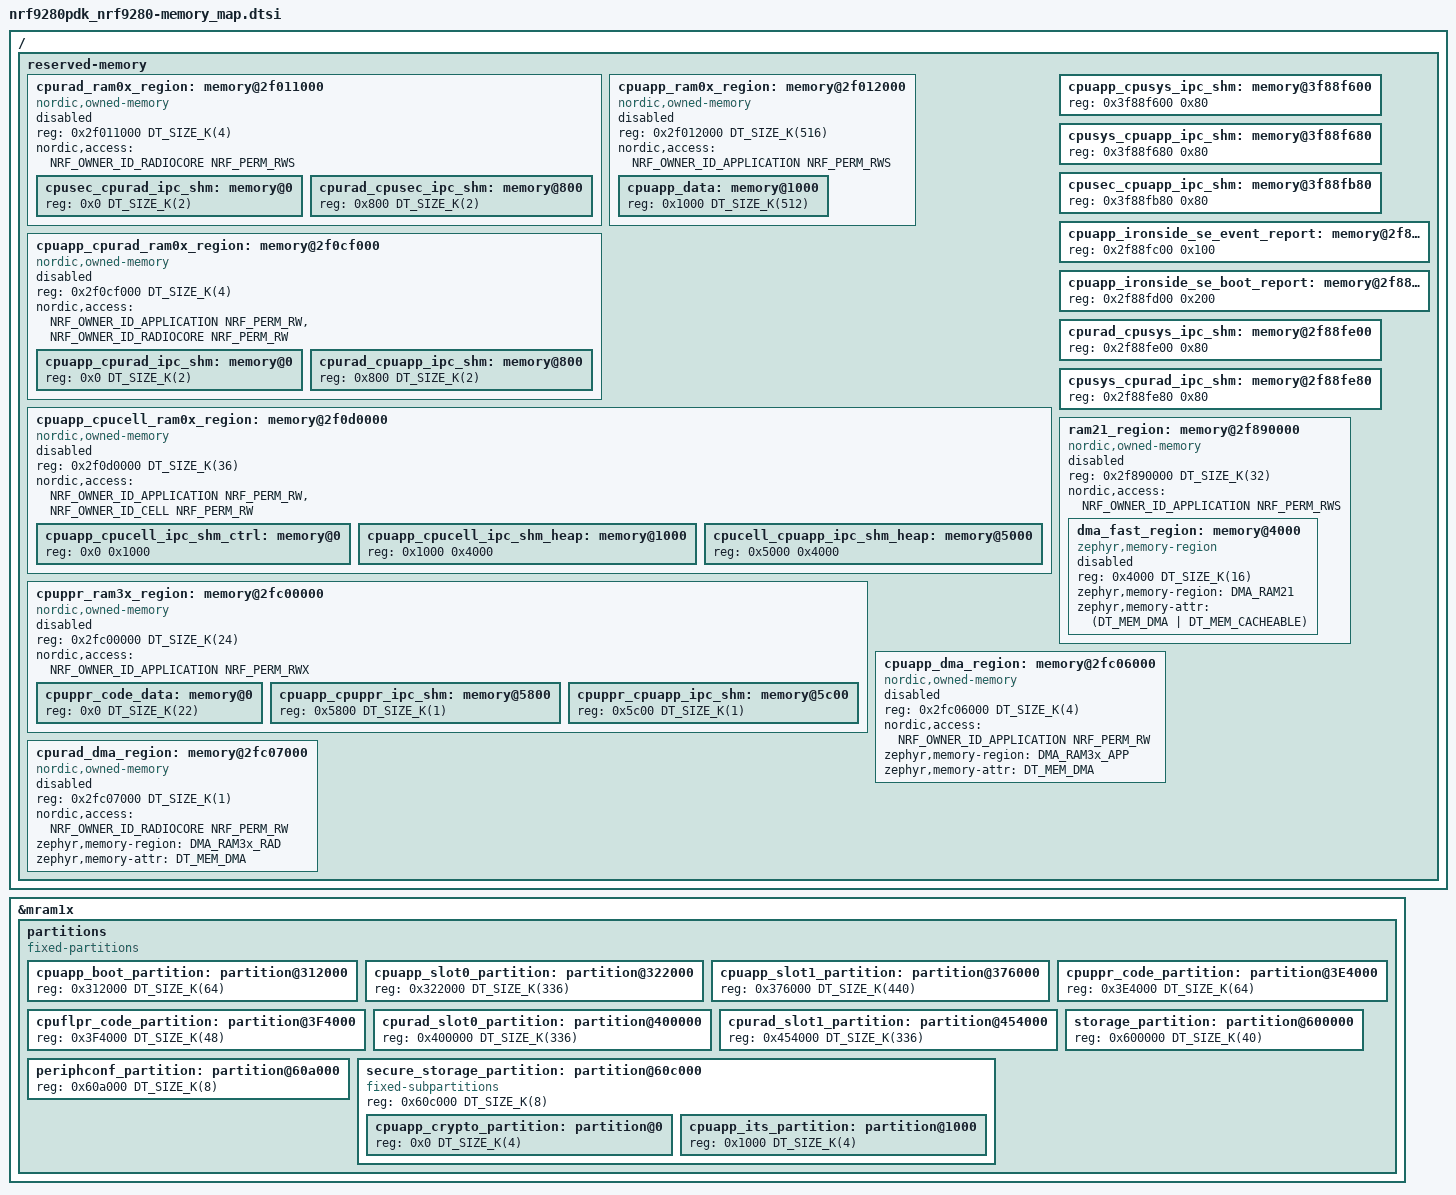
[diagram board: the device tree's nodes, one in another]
/*
 * Copyright (c) 2024 Nordic Semiconductor ASA
 *
 * SPDX-License-Identifier: Apache-2.0
 */
#include <zephyr/dt-bindings/memory-attr/memory-attr.h>

/ {
	reserved-memory {
		/* The first 64kb are reserved for SecDom.
		 * The next 4kb are reserved for IPC between SecDom and Cellcore.
		 */

		cpurad_ram0x_region: memory@2f011000 {
			compatible = "nordic,owned-memory";
			reg = <0x2f011000 DT_SIZE_K(4)>;
			status = "disabled";
			nordic,access = <NRF_OWNER_ID_RADIOCORE NRF_PERM_RWS>;
			#address-cells = <1>;
			#size-cells = <1>;
			ranges = <0x0 0x2f011000 0x1000>;

			cpusec_cpurad_ipc_shm: memory@0 {
				reg = <0x0 DT_SIZE_K(2)>;
			};

			cpurad_cpusec_ipc_shm: memory@800 {
				reg = <0x800 DT_SIZE_K(2)>;
			};
		};

		cpuapp_ram0x_region: memory@2f012000 {
			compatible = "nordic,owned-memory";
			reg = <0x2f012000 DT_SIZE_K(516)>;
			status = "disabled";
			nordic,access = <NRF_OWNER_ID_APPLICATION NRF_PERM_RWS>;
			#address-cells = <1>;
			#size-cells = <1>;
			ranges = <0x0 0x2f012000 0x81000>;

			cpuapp_data: memory@1000 {
				reg = <0x1000 DT_SIZE_K(512)>;
			};
		};

		cpuapp_cpurad_ram0x_region: memory@2f0cf000 {
			compatible = "nordic,owned-memory";
			reg = <0x2f0cf000 DT_SIZE_K(4)>;
			status = "disabled";
			nordic,access = <NRF_OWNER_ID_APPLICATION NRF_PERM_RW>,
					<NRF_OWNER_ID_RADIOCORE NRF_PERM_RW>;
			#address-cells = <1>;
			#size-cells = <1>;
			ranges = <0x0 0x2f0cf000 0x1000>;

			cpuapp_cpurad_ipc_shm: memory@0 {
				reg = <0x0 DT_SIZE_K(2)>;
			};

			cpurad_cpuapp_ipc_shm: memory@800 {
				reg = <0x800 DT_SIZE_K(2)>;
			};
		};

		cpuapp_cpucell_ram0x_region: memory@2f0d0000 {
			compatible = "nordic,owned-memory";
			reg = <0x2f0d0000 DT_SIZE_K(36)>;
			status = "disabled";
			nordic,access = <NRF_OWNER_ID_APPLICATION NRF_PERM_RW>,
					<NRF_OWNER_ID_CELL NRF_PERM_RW>;
			#address-cells = <1>;
			#size-cells = <1>;
			ranges = <0x0 0x2f0d0000 0x9000>;

			/* Control region, with ICmsg buffers.
			 * Size is fixed.
			 */
			cpuapp_cpucell_ipc_shm_ctrl: memory@0 {
				reg = <0x0 0x1000>;
			};

			/* TX heap, user defined */
			cpuapp_cpucell_ipc_shm_heap: memory@1000 {
				reg = <0x1000 0x4000>;
			};

			/* RX heap, user defined */
			cpucell_cpuapp_ipc_shm_heap: memory@5000 {
				reg = <0x5000 0x4000>;
			};
		};

		/* Workaround for a data cache related issue with SoC1.1, use secure addresses
		 * for cpuapp_cpusys_ipc_shm, cpusys_cpuapp_ipc_shm and cpusec_cpuapp_ipc_shm.
		 */
		cpuapp_cpusys_ipc_shm: memory@3f88f600 {
			reg = <0x3f88f600 0x80>;
		};

		cpusys_cpuapp_ipc_shm: memory@3f88f680 {
			reg = <0x3f88f680 0x80>;
		};

		cpusec_cpuapp_ipc_shm: memory@3f88fb80 {
			reg = <0x3f88fb80 0x80>;
		};

		cpuapp_ironside_se_event_report: memory@2f88fc00 {
			reg = <0x2f88fc00 0x100>;
		};

		cpuapp_ironside_se_boot_report: memory@2f88fd00 {
			reg = <0x2f88fd00 0x200>;
		};

		cpurad_cpusys_ipc_shm: memory@2f88fe00 {
			reg = <0x2f88fe00 0x80>;
		};

		cpusys_cpurad_ipc_shm: memory@2f88fe80 {
			reg = <0x2f88fe80 0x80>;
		};

		ram21_region: memory@2f890000 {
			compatible = "nordic,owned-memory";
			status = "disabled";
			reg = <0x2f890000 DT_SIZE_K(32)>;
			nordic,access = <NRF_OWNER_ID_APPLICATION NRF_PERM_RWS>;
			#address-cells = <1>;
			#size-cells = <1>;
			ranges = <0x0 0x2f890000 0x8000>;

			dma_fast_region: memory@4000 {
				compatible = "zephyr,memory-region";
				reg = <0x4000 DT_SIZE_K(16)>;
				status = "disabled";
				#memory-region-cells = <0>;
				zephyr,memory-region = "DMA_RAM21";
				zephyr,memory-attr = <(DT_MEM_DMA | DT_MEM_CACHEABLE)>;
			};
		};

		cpuppr_ram3x_region: memory@2fc00000 {
			compatible = "nordic,owned-memory";
			reg = <0x2fc00000 DT_SIZE_K(24)>;
			status = "disabled";
			nordic,access = <NRF_OWNER_ID_APPLICATION NRF_PERM_RWX>;
			#address-cells = <1>;
			#size-cells = <1>;
			ranges = <0x0 0x2fc00000 0x6000>;

			cpuppr_code_data: memory@0 {
				reg = <0x0 DT_SIZE_K(22)>;
			};

			cpuapp_cpuppr_ipc_shm: memory@5800 {
				reg = <0x5800 DT_SIZE_K(1)>;
			};

			cpuppr_cpuapp_ipc_shm: memory@5c00 {
				reg = <0x5c00 DT_SIZE_K(1)>;
			};
		};

		cpuapp_dma_region: memory@2fc06000 {
			compatible = "nordic,owned-memory", "zephyr,memory-region";
			reg = <0x2fc06000 DT_SIZE_K(4)>;
			status = "disabled";
			#memory-region-cells = <0>;
			nordic,access = <NRF_OWNER_ID_APPLICATION NRF_PERM_RW>;
			zephyr,memory-region = "DMA_RAM3x_APP";
			zephyr,memory-attr = <DT_MEM_DMA>;
		};

		cpurad_dma_region: memory@2fc07000 {
			compatible = "nordic,owned-memory", "zephyr,memory-region";
			reg = <0x2fc07000 DT_SIZE_K(1)>;
			status = "disabled";
			#memory-region-cells = <0>;
			nordic,access = <NRF_OWNER_ID_RADIOCORE NRF_PERM_RW>;
			zephyr,memory-region = "DMA_RAM3x_RAD";
			zephyr,memory-attr = <DT_MEM_DMA>;
		};
	};
};

&mram1x {
	partitions {
		compatible = "fixed-partitions";
		#address-cells = <1>;
		#size-cells = <1>;

		cpuapp_boot_partition: partition@312000 {
			reg = <0x312000 DT_SIZE_K(64)>;
		};

		cpuapp_slot0_partition: partition@322000 {
			reg = <0x322000 DT_SIZE_K(336)>;
		};

		cpuapp_slot1_partition: partition@376000 {
			reg = <0x376000 DT_SIZE_K(440)>;
		};

		cpuppr_code_partition: partition@3E4000 {
			reg = <0x3E4000 DT_SIZE_K(64)>;
		};

		cpuflpr_code_partition: partition@3F4000 {
			reg = <0x3F4000 DT_SIZE_K(48)>;
		};

		cpurad_slot0_partition: partition@400000 {
			reg = <0x400000 DT_SIZE_K(336)>;
		};

		cpurad_slot1_partition: partition@454000 {
			reg = <0x454000 DT_SIZE_K(336)>;
		};

		storage_partition: partition@600000 {
			reg = <0x600000 DT_SIZE_K(40)>;
		};

		periphconf_partition: partition@60a000 {
			reg = <0x60a000 DT_SIZE_K(8)>;
		};

		/* 0x60c000 was chosen for secure_storage_partition such that
		 * it resides in the beginning of MRAM11 in storage partition.
		 */
		secure_storage_partition: partition@60c000 {
			compatible = "fixed-subpartitions";
			reg = <0x60c000 DT_SIZE_K(8)>;
			ranges = <0x0 0x60c000 0x2000>;
			#address-cells = <1>;
			#size-cells = <1>;

			cpuapp_crypto_partition: partition@0 {
				reg = <0x0 DT_SIZE_K(4)>;
			};

			cpuapp_its_partition: partition@1000 {
				reg = <0x1000 DT_SIZE_K(4)>;
			};
		};
	};
};
